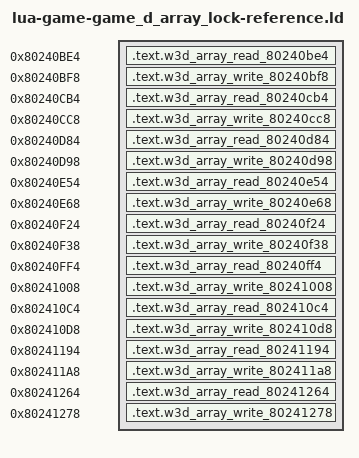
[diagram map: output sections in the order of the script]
/* Generated reference-only placements. All bodies are source-built. */
OUTPUT_FORMAT("elf32-powerpc")
OUTPUT_ARCH(powerpc)
ENTRY(w3d_array_read_80240be4)
_SDA_BASE_ = 0x804b2540;
_SDA2_BASE_ = 0x804c2540;
w3d_array_reserve_801ef048 = 0x801ef048;
SECTIONS {
  .text.w3d_array_read_80240be4 0x80240be4 : { *(.text.w3d_array_read_80240be4) }
  .text.w3d_array_write_80240bf8 0x80240bf8 : { *(.text.w3d_array_write_80240bf8) }
  .text.w3d_array_read_80240cb4 0x80240cb4 : { *(.text.w3d_array_read_80240cb4) }
  .text.w3d_array_write_80240cc8 0x80240cc8 : { *(.text.w3d_array_write_80240cc8) }
  .text.w3d_array_read_80240d84 0x80240d84 : { *(.text.w3d_array_read_80240d84) }
  .text.w3d_array_write_80240d98 0x80240d98 : { *(.text.w3d_array_write_80240d98) }
  .text.w3d_array_read_80240e54 0x80240e54 : { *(.text.w3d_array_read_80240e54) }
  .text.w3d_array_write_80240e68 0x80240e68 : { *(.text.w3d_array_write_80240e68) }
  .text.w3d_array_read_80240f24 0x80240f24 : { *(.text.w3d_array_read_80240f24) }
  .text.w3d_array_write_80240f38 0x80240f38 : { *(.text.w3d_array_write_80240f38) }
  .text.w3d_array_read_80240ff4 0x80240ff4 : { *(.text.w3d_array_read_80240ff4) }
  .text.w3d_array_write_80241008 0x80241008 : { *(.text.w3d_array_write_80241008) }
  .text.w3d_array_read_802410c4 0x802410c4 : { *(.text.w3d_array_read_802410c4) }
  .text.w3d_array_write_802410d8 0x802410d8 : { *(.text.w3d_array_write_802410d8) }
  .text.w3d_array_read_80241194 0x80241194 : { *(.text.w3d_array_read_80241194) }
  .text.w3d_array_write_802411a8 0x802411a8 : { *(.text.w3d_array_write_802411a8) }
  .text.w3d_array_read_80241264 0x80241264 : { *(.text.w3d_array_read_80241264) }
  .text.w3d_array_write_80241278 0x80241278 : { *(.text.w3d_array_write_80241278) }
  /DISCARD/ : { *(.text*) *(.rodata*) *(.data*) *(.bss*) *(.sdata*) *(.sbss*) *(.comment) }
}
